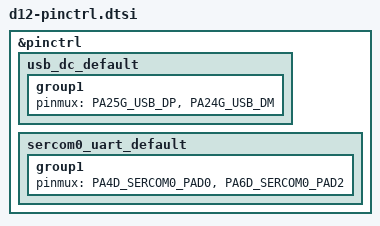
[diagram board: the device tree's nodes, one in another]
/*
 * Copyright (c) 2022, Gerson Fernando Budke <nandojve@gmail.com>
 * SPDX-License-Identifier: Apache-2.0
 */

#include <dt-bindings/pinctrl/samd21-da1eXabcd-pinctrl.h>

&pinctrl {
	usb_dc_default: usb_dc_default {
		group1 {
			pinmux = <PA25G_USB_DP>,
				 <PA24G_USB_DM>;
		};
	};
	sercom0_uart_default: sercom0_uart_default {
		group1 {
			pinmux = <PA4D_SERCOM0_PAD0>,
				<PA6D_SERCOM0_PAD2>;
		};
	};
};
